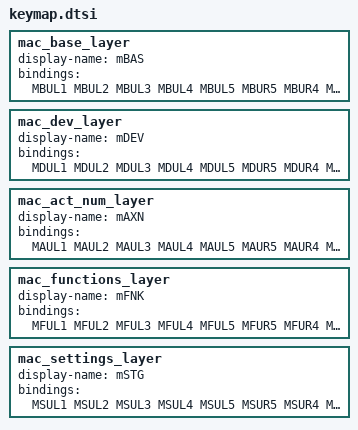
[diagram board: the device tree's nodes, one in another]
        mac_base_layer {
            #define MBUL1  &kp Q                         // tap: q ¦ shift: Q
            #define MBUL2  &kp W                         // tap: w ¦ shift: W
            #define MBUL3  &kp F                         // tap: f ¦ shift: F
            #define MBUL4  &kp P                         // tap: p ¦ shift: P
            #define MBUL5  &kp B                         // tap: b ¦ shift: B

            #define MBML1  &hm_mBAS_LC LCTRL 0           // tap: a ¦ shift: A ¦ alt: á ¦ alt+shift: Á ¦ hold: CONTROL
            #define MBML2  &hm LCMD  R                   // tap: r ¦ shift: R ¦        ¦              ¦ hold: COMMAND
            #define MBML3  &hm LALT  S                   // tap: s ¦ shift: S ¦        ¦              ¦ hold: ALT
            #define MBML4  &hm LSHFT T                   // tap: t ¦ shift: T ¦        ¦              ¦ hold: SHIFT
            #define MBML5  &kp G                         // tap: g ¦ shift: G

            #define MBBL1  &kp Z                         // tap: z ¦ shift: Z
            #define MBBL2  &kp X                         // tap: x ¦ shift: X
            #define MBBL3  &kp C                         // tap: c ¦ shift: C
            #define MBBL4  &kp D                         // tap: d ¦ shift: D
            #define MBBL5  &kp V                         // tap: v ¦ shift: V

            #define MBUR5  &kp J                         // tap: j ¦ shift: J
            #define MBUR4  &kp L                         // tap: l ¦ shift: L
            #define MBUR3  &mp_mi_u                      // tap: u ¦ shift: U ¦ alt: ú ¦ alt+shift: Ú
            #define MBUR2  &mp_mi_y                      // tap: y ¦ shift: Y ¦ alt: ü ¦ alt+shift: Ü
            #define MBUR1  &mp_k_m                       // tap: - ¦ shift: _ 

            #define MBMR5  &kp M                         // tap: m ¦ shift: M
            #define MBMR4  &hm_mBAS_RS RSHFT 0           // tap: n ¦ shift: N ¦ alt: ñ ¦ alt+shift: Ñ ¦ hold: SHIFT
            #define MBMR3  &hm_mBAS_RA LALT  0           // tap: e ¦ shift: E ¦ alt: é ¦ alt+shift: É ¦ hold: ALT
            #define MBMR2  &hm_mBAS_RC RCMD  0           // tap: i ¦ shift: I ¦ alt: í ¦ alt+shift: Í ¦ hold: COMMAND
            #define MBMR1  &hm_mBAS_RG RCTRL 0           // tap: o ¦ shift: O ¦ alt: ó ¦ alt+shift: Ó ¦ hold: CONTROL

            #define MBBR5  &kp K                         // tap: k ¦ shift: K 
            #define MBBR4  &kp H                         // tap: h ¦ shift: H 
            #define MBBR3  &mp_k_cs                      // tap: , ¦ shift: ;
            #define MBBR2  &mp_k_dc                      // tap: . ¦ shift: :
            #define MBBR1  &mp_mk_q                      // tap: ' ¦ shift: "

            #define MBTL0  MKY_ESC                       // tap: escape      ¦ shift: caps lock    ¦ hold: BAS layer
            #define MBTL1  &mp_mk_dev_right              // tap: right arrow ¦ shift: to DEV layer ¦ long-tap: to DEV momentary
            #define MBTL2  KEY_SPC                       // tap: blank space
            #define MBTL3  &mp_mk_axn                    // tap: tab         ¦ shift: to AXN layer ¦ long-tap: to AXN momentary

            #define MBTR3  &mp_mk_fnk                    // tap: back space  ¦ shift: to AXN layer ¦ long-tap: to FNK momentary
            #define MBTR2  MKY_RET                       // tap: return      ¦                     ¦ hold: F2 (easy rename on ide)                  
            #define MBTR1  &mp_mk_dev_left               // tap: delete      ¦ shift: to DEV layer ¦ long-tap: to DEV momentary
            #define MBTR0  &mp_mk_stg                    //                  ¦ shift: to STG layer ¦ long-tap: to STG momentary


            display-name = "mBAS";
            bindings = <
                     MBUL1  MBUL2  MBUL3  MBUL4  MBUL5    MBUR5  MBUR4  MBUR3  MBUR2  MBUR1
                     MBML1  MBML2  MBML3  MBML4  MBML5    MBMR5  MBMR4  MBMR3  MBMR2  MBMR1
              MBTL0  MBBL1  MBBL2  MBBL3  MBBL4  MBBL5    MBBR5  MBBR4  MBBR3  MBBR2  MBBR1  MBTR0
                                   MBTL1  MBTL2  MBTL3    MBTR3  MBTR2  MBTR1
            >;
        };

        mac_dev_layer {
            #define MDUL1  &kp AT                        // tap: @
            #define MDUL2  &mp_mDEV_pound                // tap: # ¦ alt: °
            #define MDUL3  &mp_mDEV_money                // tap: $ ¦ alt: €
            #define MDUL4  &kp PLUS                      // tap: +
            #define MDUL5  &m_mi_d                       // tap: "

            #define MDML1  &hm LCTRL AMPS                // tap: & ¦ hold: CONTROL
            #define MDML2  &hm LCMD  LBRC                // tap: { ¦ hold: COMMAND
            #define MDML3  &hm LALT  RBRC                // tap: } ¦ hold: ALT
            #define MDML4  &hm LSHFT EQUAL               // tap: = ¦ hold: SHIFT
            #define MDML5  &m_mi_s                       // tap: '

            #define MDBL1  &kp LG(R)                     // tap: reload ¦ shift: hard reload
            #define MDBL2  &kp LPAR                      // tap: (
            #define MDBL3  &kp RPAR                      // tap: )
            #define MDBL4  &kp ASTRK                     // tap: *
            #define MDBL5  &kp BSLH                      // tap: \

            #define MDUR5  &m_mi_t                       // tap: ~
            #define MDUR4  &kp MINUS                     // tap: -
            #define MDUR3  &kp UNDER                     // tap: _
            #define MDUR2  &kp PRCNT                     // tap: %
            #define MDUR1  &m_mi_c                       // tap: ^

            #define MDMR5  &m_mi_g                       // tap: `
            #define MDMR4  &hm_mDEV_RS RSHFT 0           // tap: ! ¦ alt: ¡ ¦ hold: SHIFT
            #define MDMR3  &hm_mDEV_RA LALT  0           // tap: [ ¦ alt: « ¦ hold: ALT
            #define MDMR2  &hm_mDEV_RC RCMD  0           // tap: ] ¦ alt: » ¦ hold: COMMAND
            #define MDMR1  &hm RCTRL PIPE                // tap: | ¦        ¦ hold: CONTROL

            #define MDBR5  &kp FSLH                      // tap: / 
            #define MDBR4  &mp_mDEV_qs                   // tap: ?  ¦ alt: ¿
            #define MDBR3  &kp LT                        // tap: <
            #define MDBR2  &kp GT                        // tap: >
            #define MDBR1  &mp_mDEV_ql                   // tap: ?. ¦ shift: ?░:░

            #define MDTL0  MKY_ESC                       // tap: escape ¦ shift: caps lock ¦ hold: BAS layer
            #define MDTL1  &none
            #define MDTL2  &kp LG(L)                     // tap: cursor add to chat
            #define MDTL3  &kp LG(K)                     // tap: cursor quick edit

            #define MDTR3  &kp LG(FSLH)                  // tap: // line comment
            #define MDTR2  &kp LA(LS(A))                 // tap: /* block comment */ 
            #define MDTR1  &none
            #define MDTR0  &kp LA(LG(I))                 // tap: dev tools


            display-name = "mDEV";
            bindings = <
                     MDUL1  MDUL2  MDUL3  MDUL4  MDUL5    MDUR5  MDUR4  MDUR3  MDUR2  MDUR1
                     MDML1  MDML2  MDML3  MDML4  MDML5    MDMR5  MDMR4  MDMR3  MDMR2  MDMR1
              MDTL0  MDBL1  MDBL2  MDBL3  MDBL4  MDBL5    MDBR5  MDBR4  MDBR3  MDBR2  MDBR1  MDTR0
                                   MDTL1  MDTL2  MDTL3    MDTR3  MDTR2  MDTR1
            >;
        };

        mac_act_num_layer {
            #define MAUL1  &kp  LC(LS(LG(RIGHT)))        // tap: expand selection
            #define MAUL2  &mp_ma_prev                   // tap: prev tab ¦ shift: prev desktop
            #define MAUL3  &kp UP                        // tap: up arrow
            #define MAUL4  &mp_ma_next                   // tap: next tab ¦ shift: next desktop
            #define MAUL5  &kp  LG(F)                    // tap: find

            #define MAML1  &hm LCTRL LC(LS(LG(LEFT)))    // tap: shrink selection ¦ hold: CONTROL
            #define MAML2  &hm LCMD  LEFT                // tap: left arrow ¦ hold: COMMAND
            #define MAML3  &hm LALT  DOWN                // tap: down arrow ¦ hold: ALT
            #define MAML4  &hm LSHFT RIGHT               // tap: right arrow ¦ hold: SHIFT
            #define MAML5  &kp LA(LG(F))                 // tap: replace

            #define MABL1  &kp RG(Z)                     // tap: undo
            #define MABL2  &kp RG(X)                     // tap: cut
            #define MABL3  &kp RG(C)                     // tap: copy
            #define MABL4  &mp_ma_paste                  // tap: paste ¦ shift: paste without format
            #define MABL5  &kp RS(RG(Z))                 // tap: redo

            #define MAUR5  &kp KP_PLUS                   // tap: +     
            #define MAUR4  &kp N7                        // tap: 7
            #define MAUR3  &kp N8                        // tap: 8
            #define MAUR2  &kp N9                        // tap: 9
            #define MAUR1  &kp KP_MULTIPLY               // tap: *

            #define MAMR5  &kp N0                        // tap: 0
            #define MAMR4  &hm LSHFT N4                  // tap: 4 ¦ hold: SHIFT
            #define MAMR3  &hm LALT  N5                  // tap: 5 ¦ hold: ALT
            #define MAMR2  &hm LCMD  N6                  // tap: 6 ¦ hold: COMMAND 
            #define MAMR1  &hm LCTRL EQUAL               // tap: = ¦ hold: CONTROL

            #define MABR5  &kp MINUS                     // tap: -
            #define MABR4  &kp N1                        // tap: 1
            #define MABR3  &kp N2                        // tap: 2
            #define MABR2  &kp N3                        // tap: 3
            #define MABR1  &kp KP_DIVIDE                 // tap: /

            #define MATL0  MKY_ESC                       // tap: escape ¦ shift: caps lock ¦ hold: BAS layer
            #define MATL1  &none
            #define MATL2  &none
            #define MATL3  &none

            #define MATR3  &none
            #define MATR2  &kp DOT                       // tap: .
            #define MATR1  &none
            #define MATR0  &none


            display-name = "mAXN";
            bindings = <
                     MAUL1  MAUL2  MAUL3  MAUL4  MAUL5    MAUR5  MAUR4  MAUR3  MAUR2  MAUR1
                     MAML1  MAML2  MAML3  MAML4  MAML5    MAMR5  MAMR4  MAMR3  MAMR2  MAMR1
              MATL0  MABL1  MABL2  MABL3  MABL4  MABL5    MABR5  MABR4  MABR3  MABR2  MABR1  MATR0
                                   MATL1  MATL2  MATL3    MATR3  MATR2  MATR1
            >;
        };

        mac_functions_layer {
            #define MFUL1  &kp F9                        // tap: F9
            #define MFUL2  &kp F10                       // tap: F10
            #define MFUL3  &kp F11                       // tap: F11
            #define MFUL4  &kp F12                       // tap: F12
            #define MFUL5  &none

            #define MFML1  &hm LCMD  F5                  // tap: F5 ¦ hold: COMMAND
            #define MFML2  &hm LCTRL F6                  // tap: F6 ¦ hold: CONTROL
            #define MFML3  &hm LALT  F7                  // tap: F7 ¦ hold: ALT
            #define MFML4  &hm LSHFT F8                  // tap: F8 ¦ hold: SHIFT
            #define MFML5  &none

            #define MFBL1  &kp F1                        // tap: F1
            #define MFBL2  &kp F2                        // tap: F2
            #define MFBL3  &kp F3                        // tap: F3
            #define MFBL4  &kp F4                        // tap: F4
            #define MFBL5  &none

            #define MFUR5  &none
            #define MFUR4  &none
            #define MFUR3  &kp PG_UP                     // tap: page up
            #define MFUR2  &none
            #define MFUR1  &none

            #define MFMR5  &none
            #define MFMR4  &hm RSHFT HOME                // tap: home      ¦ hold: SHIFT
            #define MFMR3  &hm LALT  PG_DN               // tap: page down ¦ hold: ALT
            #define MFMR2  &hm RCTRL END                 // tap: end       ¦ hold: CONTROL
            #define MFMR1  &none

            #define MFBR5  &none
            #define MFBR4  &none
            #define MFBR3  &none
            #define MFBR2  &none
            #define MFBR1  &none

            #define MFTL0  MKY_ESC                       // tap: escape ¦ shift: caps lock ¦ hold: BAS layer
            #define MFTL1  &none
            #define MFTL2  &none
            #define MFTL3  &none

            #define MFTR3  &none
            #define MFTR2  &none
            #define MFTR1  &none
            #define MFTR0  &none


            display-name = "mFNK";
            bindings = <
                     MFUL1  MFUL2  MFUL3  MFUL4  MFUL5    MFUR5  MFUR4  MFUR3  MFUR2  MFUR1
                     MFML1  MFML2  MFML3  MFML4  MFML5    MFMR5  MFMR4  MFMR3  MFMR2  MFMR1
              MFTL0  MFBL1  MFBL2  MFBL3  MFBL4  MFBL5    MFBR5  MFBR4  MFBR3  MFBR2  MFBR1  MFTR0
                                   MFTL1  MFTL2  MFTL3    MFTR3  MFTR2  MFTR1
            >;
        };

        mac_settings_layer {
            #define MSUL1  &m_s_b1                       // tap: bluethoot 1
            #define MSUL2  &m_s_b2                       // tap: bluethoot 2
            #define MSUL3  &none
            #define MSUL4  &kp LG(LS(C))                 // tap: color picker
            #define MSUL5  &kp RG(PLUS)                  // tap: zoom in

            #define MSML1  &hm_mSTG_LC  LCTRL  0         // tap: bluethoot 3
            #define MSML2  &m_s_b4                       // tap: bluethoot 4
            #define MSML3  &kp LALT                      // hold: ALT
            #define MSML4  &hm_mSTG_LS  LSHFT  0         // tap: mp_mSTG_screenshot ¦ hold: SHIFT
            #define MSML5  &mp_mSTG_z                    // tap: zoom reset ¦ shift: zoom reset on vscode

            #define MSBL1  &kp C_BRI_DN                  // tap: bright down
            #define MSBL2  &kp C_BRI_UP                  // tap: bright up
            #define MSBL3  &none
            #define MSBL4  &mp_mSTG_f                    // tap: (finder) file explorer ¦ alt: show/hide system files
            #define MSBL5  &kp RG(MINUS)                 // tap: zoom out

            #define MSUR5  &kp C_VOL_UP
            #define MSUR4  &mp_mSTG_topleft              // tap: ide explorer ¦ alt: rectangle top left
            #define MSUR3  &mp_mSTG_up                   // tap: ide source control ¦ alt: rectangle top halt
            #define MSUR2  &mp_mSTG_topright             // tap: ide debugger ¦ alt: rectangle top right
            #define MSUR1  &kp LC(LS(LG(T)))             // tap: todo extension

            #define MSMR5  &mp_mSTG_m                    // tap: vol mute ¦ shift: mic mute
            #define MSMR4  &hm_mSTG_RS  LSHIFT  0        // tap: mp_mSTG_left
            #define MSMR3  &hm_mSTG_RA  LALT    0        // tap: mp_mSTG_rectangle
            #define MSMR2  &mp_mSTG_right                // tap: ide secondary side bar ¦ alt: rectangle right
            #define MSMR1  &kp LC(UP)                    // tap: mission control

            #define MSBR5  &kp C_VOL_DN
            #define MSBR4  &mp_mSTG_downleft             // tap: none ¦ alt: rectangle bottom left
            #define MSBR3  &mp_mSTG_down                 // tap: ide panel bottom bar ¦ alt: rectangle bottom down
            #define MSBR2  &mp_mSTG_downright            // tap: none ¦ alt: rectangle bottom right
            #define MSBR1  &kp LC(DOWN)                  // tap: application window               

            #define MSTL0  MKY_ESC                       // tap: escape ¦ shift: caps lock ¦ hold: BAS layer
            #define MSTL1  &mp_sSTG_cb                   // tap: none ¦ shift: clear current profile ¦ alt: clear all profiles
            #define MSTL2  &none
            #define MSTL3  &none

            #define MSTR3  &none
            #define MSTR2  &none
            #define MSTR1  &none
            #define MSTR0  &none


            display-name = "mSTG";
            bindings = <
                     MSUL1  MSUL2  MSUL3  MSUL4  MSUL5    MSUR5  MSUR4  MSUR3  MSUR2  MSUR1
                     MSML1  MSML2  MSML3  MSML4  MSML5    MSMR5  MSMR4  MSMR3  MSMR2  MSMR1
              MSTL0  MSBL1  MSBL2  MSBL3  MSBL4  MSBL5    MSBR5  MSBR4  MSBR3  MSBR2  MSBR1  MSTR0
                                   MSTL1  MSTL2  MSTL3    MSTR3  MSTR2  MSTR1
            >;
        };
